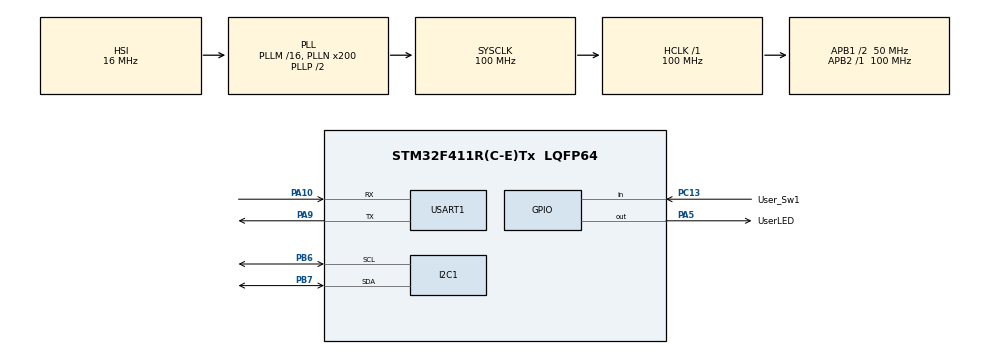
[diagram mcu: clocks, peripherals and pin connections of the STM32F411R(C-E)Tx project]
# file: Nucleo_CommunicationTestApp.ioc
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Mcu.Family=STM32F4
Mcu.Name=STM32F411R(C-E)Tx
Mcu.Package=LQFP64
NVIC.PriorityGroup=NVIC_PRIORITYGROUP_4
PA10.Mode=Asynchronous
PA10.Signal=USART1_RX
PA13.Mode=Serial_Wire
PA13.Signal=SYS_JTMS-SWDIO
PA14.Mode=Serial_Wire
PA14.Signal=SYS_JTCK-SWCLK
PA5.GPIO_Label=UserLED
PA5.Signal=GPIO_Output
PA9.Mode=Asynchronous
PA9.Signal=USART1_TX
PB6.Mode=I2C
PB6.Signal=I2C1_SCL
PB7.Mode=I2C
PB7.Signal=I2C1_SDA
PC13-ANTI_TAMP.GPIO_Label=User_Sw1
PC13-ANTI_TAMP.GPIO_PuPd=GPIO_PULLUP
PC13-ANTI_TAMP.Signal=GPIO_Input
ProjectManager.HeapSize=0x200
ProjectManager.StackSize=0x400
ProjectManager.TargetToolchain=STM32CubeIDE
RCC.48MHZClocksFreq_Value=50000000
RCC.AHBFreq_Value=100000000
RCC.APB1CLKDivider=RCC_HCLK_DIV2
RCC.APB1Freq_Value=50000000
RCC.APB1TimFreq_Value=100000000
RCC.APB2Freq_Value=100000000
RCC.APB2TimFreq_Value=100000000
RCC.CortexFreq_Value=100000000
RCC.HCLKFreq_Value=100000000
RCC.HSE_VALUE=25000000
RCC.HSI_VALUE=16000000
RCC.LSE_VALUE=32768
RCC.PLLN=200
RCC.SYSCLKFreq_VALUE=100000000
RCC.SYSCLKSource=RCC_SYSCLKSOURCE_PLLCLK
RCC.VCOOutputFreq_Value=200000000
USART1.VirtualMode=VM_ASYNC
board=custom

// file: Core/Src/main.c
/* USER CODE BEGIN Header */
/**
  ******************************************************************************
  * @file           : main.c
  * @brief          : Main program body
  ******************************************************************************
  * @attention
  *
  * <h2><center>&copy; Copyright (c) 2020 STMicroelectronics.
  * All rights reserved.</center></h2>
  *
  * This software component is licensed by ST under BSD 3-Clause license,
  * the "License"; You may not use this file except in compliance with the
  * License. You may obtain a copy of the License at:
  *                        opensource.org/licenses/BSD-3-Clause
  *
  ******************************************************************************
  */
/* USER CODE END Header */
#include "main.h"

I2C_HandleTypeDef hi2c1;

UART_HandleTypeDef huart1;

void SystemClock_Config(void);
static void MX_GPIO_Init(void);
static void MX_I2C1_Init(void);
static void MX_USART1_UART_Init(void);

int main(void)
{

  /* MCU Configuration--------------------------------------------------------*/

  /* Reset of all peripherals, Initializes the Flash interface and the Systick. */
  HAL_Init();

  /* Configure the system clock */
  SystemClock_Config();

  /* Initialize all configured peripherals */
  MX_GPIO_Init();
  MX_I2C1_Init();
  MX_USART1_UART_Init();

  /* Infinite loop */
  while (1)
  {

    /* USER CODE BEGIN 3 */
	  // service of the UART
	  // Service of the I2C

	  // Test for led
	  if (0 == HAL_GPIO_ReadPin(User_Sw1_GPIO_Port, User_Sw1_Pin))
		  HAL_GPIO_WritePin(UserLED_GPIO_Port, UserLED_Pin, GPIO_PIN_SET);
	  else
		  HAL_GPIO_WritePin(UserLED_GPIO_Port, UserLED_Pin, GPIO_PIN_RESET);
  }
  /* USER CODE END 3 */
}

void SystemClock_Config(void)
{
  RCC_OscInitTypeDef RCC_OscInitStruct = {0};
  RCC_ClkInitTypeDef RCC_ClkInitStruct = {0};

  /** Configure the main internal regulator output voltage
  */
  __HAL_RCC_PWR_CLK_ENABLE();
  __HAL_PWR_VOLTAGESCALING_CONFIG(PWR_REGULATOR_VOLTAGE_SCALE1);
  /** Initializes the RCC Oscillators according to the specified parameters
  * in the RCC_OscInitTypeDef structure.
  */
  RCC_OscInitStruct.OscillatorType = RCC_OSCILLATORTYPE_HSI;
  RCC_OscInitStruct.HSIState = RCC_HSI_ON;
  RCC_OscInitStruct.HSICalibrationValue = RCC_HSICALIBRATION_DEFAULT;
  RCC_OscInitStruct.PLL.PLLState = RCC_PLL_ON;
  RCC_OscInitStruct.PLL.PLLSource = RCC_PLLSOURCE_HSI;
  RCC_OscInitStruct.PLL.PLLM = 16;
  RCC_OscInitStruct.PLL.PLLN = 200;
  RCC_OscInitStruct.PLL.PLLP = RCC_PLLP_DIV2;
  RCC_OscInitStruct.PLL.PLLQ = 4;
  if (HAL_RCC_OscConfig(&RCC_OscInitStruct) != HAL_OK)
  {
    Error_Handler();
  }
  /** Initializes the CPU, AHB and APB buses clocks
  */
  RCC_ClkInitStruct.ClockType = RCC_CLOCKTYPE_HCLK|RCC_CLOCKTYPE_SYSCLK
                              |RCC_CLOCKTYPE_PCLK1|RCC_CLOCKTYPE_PCLK2;
  RCC_ClkInitStruct.SYSCLKSource = RCC_SYSCLKSOURCE_PLLCLK;
  RCC_ClkInitStruct.AHBCLKDivider = RCC_SYSCLK_DIV1;
  RCC_ClkInitStruct.APB1CLKDivider = RCC_HCLK_DIV2;
  RCC_ClkInitStruct.APB2CLKDivider = RCC_HCLK_DIV1;

  if (HAL_RCC_ClockConfig(&RCC_ClkInitStruct, FLASH_LATENCY_3) != HAL_OK)
  {
    Error_Handler();
  }
}

static void MX_I2C1_Init(void)
{

  hi2c1.Instance = I2C1;
  hi2c1.Init.ClockSpeed = 100000;
  hi2c1.Init.DutyCycle = I2C_DUTYCYCLE_2;
  hi2c1.Init.OwnAddress1 = 0;
  hi2c1.Init.AddressingMode = I2C_ADDRESSINGMODE_7BIT;
  hi2c1.Init.DualAddressMode = I2C_DUALADDRESS_DISABLE;
  hi2c1.Init.OwnAddress2 = 0;
  hi2c1.Init.GeneralCallMode = I2C_GENERALCALL_DISABLE;
  hi2c1.Init.NoStretchMode = I2C_NOSTRETCH_DISABLE;
  if (HAL_I2C_Init(&hi2c1) != HAL_OK)
  {
    Error_Handler();
  }

}

static void MX_USART1_UART_Init(void)
{

  huart1.Instance = USART1;
  huart1.Init.BaudRate = 115200;
  huart1.Init.WordLength = UART_WORDLENGTH_8B;
  huart1.Init.StopBits = UART_STOPBITS_1;
  huart1.Init.Parity = UART_PARITY_NONE;
  huart1.Init.Mode = UART_MODE_TX_RX;
  huart1.Init.HwFlowCtl = UART_HWCONTROL_NONE;
  huart1.Init.OverSampling = UART_OVERSAMPLING_16;
  if (HAL_UART_Init(&huart1) != HAL_OK)
  {
    Error_Handler();
  }

}

static void MX_GPIO_Init(void)
{
  GPIO_InitTypeDef GPIO_InitStruct = {0};

  /* GPIO Ports Clock Enable */
  __HAL_RCC_GPIOC_CLK_ENABLE();
  __HAL_RCC_GPIOA_CLK_ENABLE();
  __HAL_RCC_GPIOB_CLK_ENABLE();

  /*Configure GPIO pin Output Level */
  HAL_GPIO_WritePin(UserLED_GPIO_Port, UserLED_Pin, GPIO_PIN_RESET);

  /*Configure GPIO pin : User_Sw1_Pin */
  GPIO_InitStruct.Pin = User_Sw1_Pin;
  GPIO_InitStruct.Mode = GPIO_MODE_INPUT;
  GPIO_InitStruct.Pull = GPIO_PULLUP;
  HAL_GPIO_Init(User_Sw1_GPIO_Port, &GPIO_InitStruct);

  /*Configure GPIO pin : UserLED_Pin */
  GPIO_InitStruct.Pin = UserLED_Pin;
  GPIO_InitStruct.Mode = GPIO_MODE_OUTPUT_PP;
  GPIO_InitStruct.Pull = GPIO_NOPULL;
  GPIO_InitStruct.Speed = GPIO_SPEED_FREQ_LOW;
  HAL_GPIO_Init(UserLED_GPIO_Port, &GPIO_InitStruct);

}

void Error_Handler(void)
{
}

/************************ (C) COPYRIGHT STMicroelectronics *****END OF FILE****/
